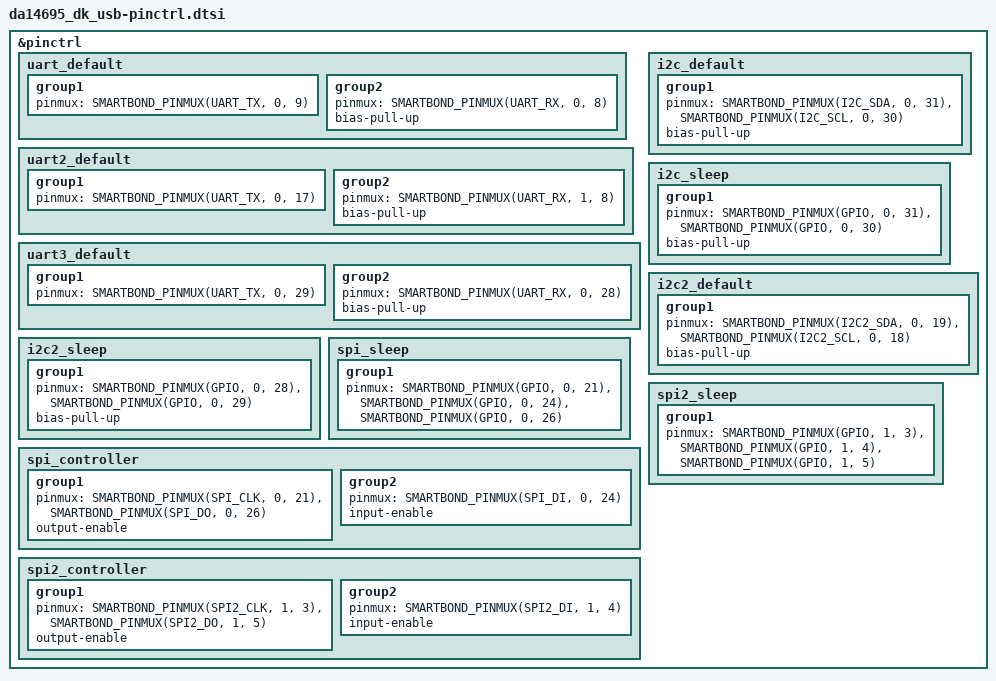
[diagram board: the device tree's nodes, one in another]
/*
 * Copyright (c) 2023 Renesas Electronics Corporation and/or its affiliates
 * SPDX-License-Identifier: Apache-2.0
 */

#include <zephyr/dt-bindings/pinctrl/smartbond-pinctrl.h>

&pinctrl {
	uart_default: uart_default {
		group1 {
			pinmux = <SMARTBOND_PINMUX(UART_TX, 0, 9)>;
		};
		group2 {
			pinmux = <SMARTBOND_PINMUX(UART_RX, 0, 8)>;
			bias-pull-up;
		};
	};

	uart2_default: uart2_default {
		group1 {
			pinmux = <SMARTBOND_PINMUX(UART_TX, 0, 17)>;
		};
		group2 {
			pinmux = <SMARTBOND_PINMUX(UART_RX, 1, 8)>;
			bias-pull-up;
		};
	};

	uart3_default: uart3_default {
		group1 {
			pinmux = <SMARTBOND_PINMUX(UART_TX, 0, 29)>;
		};
		group2 {
			pinmux = <SMARTBOND_PINMUX(UART_RX, 0, 28)>;
			bias-pull-up;
		};
	};

	i2c_default: i2c_default {
		group1 {
			pinmux = <SMARTBOND_PINMUX(I2C_SDA, 0, 31)>,
				<SMARTBOND_PINMUX(I2C_SCL, 0, 30)>;
			bias-pull-up;
		};
	};

	/omit-if-no-ref/ i2c_sleep: i2c_sleep {
		group1 {
			pinmux = <SMARTBOND_PINMUX(GPIO, 0, 31)>,
				<SMARTBOND_PINMUX(GPIO, 0, 30)>;
			bias-pull-up;

		};
	};

	i2c2_default: i2c2_default {
		group1 {
			pinmux = <SMARTBOND_PINMUX(I2C2_SDA, 0, 19)>,
				<SMARTBOND_PINMUX(I2C2_SCL, 0, 18)>;
			bias-pull-up;
		};
	};

	/omit-if-no-ref/ i2c2_sleep: i2c2_sleep {
		group1 {
			pinmux = <SMARTBOND_PINMUX(GPIO, 0, 28)>,
				<SMARTBOND_PINMUX(GPIO, 0, 29)>;
			bias-pull-up;
		};
	};

	/omit-if-no-ref/ spi_sleep: spi_sleep {
		group1 {
			pinmux = <SMARTBOND_PINMUX(GPIO, 0, 21)>,
				 <SMARTBOND_PINMUX(GPIO, 0, 24)>,
				 <SMARTBOND_PINMUX(GPIO, 0, 26)>;
		};
	};

	spi_controller: spi_controller {
		group1 {
			pinmux = < SMARTBOND_PINMUX(SPI_CLK, 0, 21) >,
				<SMARTBOND_PINMUX(SPI_DO, 0, 26)>;
			output-enable;
		};
		group2 {
			pinmux = <SMARTBOND_PINMUX(SPI_DI, 0, 24)>;
			input-enable;
		};
	};

	/omit-if-no-ref/ spi2_sleep: spi2_sleep {
		group1 {
			pinmux = <SMARTBOND_PINMUX(GPIO, 1, 3)>,
				 <SMARTBOND_PINMUX(GPIO, 1, 4)>,
				 <SMARTBOND_PINMUX(GPIO, 1, 5)>;
		};
	};

	spi2_controller: spi2_controller {
		group1 {
			pinmux = < SMARTBOND_PINMUX(SPI2_CLK, 1, 3) >,
				<SMARTBOND_PINMUX(SPI2_DO, 1, 5)>;
			output-enable;
		};
		group2 {
			pinmux = <SMARTBOND_PINMUX(SPI2_DI, 1, 4)>;
			input-enable;
		};
	};
};
